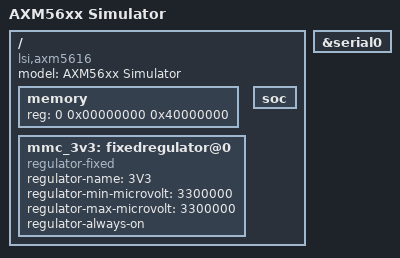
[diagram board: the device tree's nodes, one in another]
/*
 * arch/arm64/boot/dts/intel/axm5601-emu.dts
 *
 * Copyright (C) 2013 LSI
 *
 * This program is free software; you can redistribute it and/or modify
 * it under the terms of the GNU General Public License as published by
 * the Free Software Foundation; either version 2 of the License, or
 * (at your option) any later version.
 */

/dts-v1/;

#include "axm56xx.dtsi"
#include "axm5608-cpus.dtsi"

/ {
	model = "AXM56xx Simulator";
	compatible = "lsi,axm5616";

	memory {
		device_type = "memory";
		reg = <0 0x00000000 0x40000000>;
	};

	mmc_3v3: fixedregulator@0 {
		compatible = "regulator-fixed";
		regulator-name = "3V3";
		regulator-min-microvolt = <3300000>;
		regulator-max-microvolt = <3300000>;
		regulator-always-on;
	};

	soc {
	};
};

&serial0 {
	status = "okay";
};
